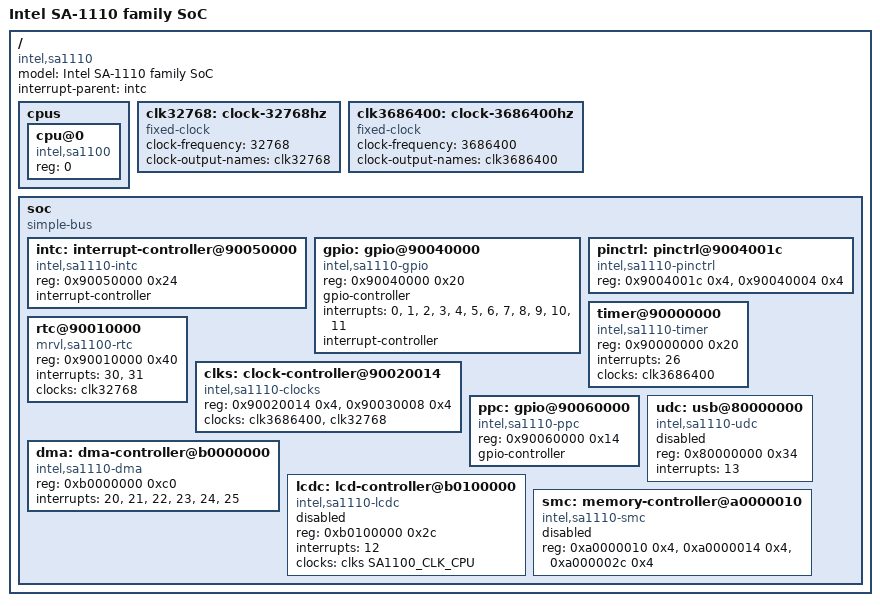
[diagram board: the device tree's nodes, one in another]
// SPDX-License-Identifier: GPL-2.0-or-later
/*
 * sa1110.dtsi - Device Tree Include file for the Intel SA-1110 SoC
 *
 * Copyright (C) 2026 Koen Kooi
 */

#include <dt-bindings/clock/intel,sa1100-clocks.h>

/ {
	#address-cells = <1>;
	#size-cells = <1>;
	model = "Intel SA-1110 family SoC";
	compatible = "intel,sa1110";
	interrupt-parent = <&intc>;

	cpus {
		#address-cells = <1>;
		#size-cells = <0>;

		cpu@0 {
			device_type = "cpu";
			/*
			 * Not "intel,sa1110": that is the board root fallback
			 * compatible, and arm/cpus.yaml matches any node with a
			 * compatible from its enum, so using it here makes the
			 * cpu schema apply to the root node as well. The
			 * SA-1100 compatible describes the same core.
			 */
			compatible = "intel,sa1100";
			reg = <0>;
		};
	};

	/* The crystal references the timer and the RTC are clocked from. */
	clk32768: clock-32768hz {
		compatible = "fixed-clock";
		#clock-cells = <0>;
		clock-frequency = <32768>;
		clock-output-names = "clk32768";
	};

	clk3686400: clock-3686400hz {
		compatible = "fixed-clock";
		#clock-cells = <0>;
		clock-frequency = <3686400>;
		clock-output-names = "clk3686400";
	};

	soc {
		compatible = "simple-bus";
		#address-cells = <1>;
		#size-cells = <1>;
		ranges;

		/* The interrupt controller has no per-line trigger type. */
		intc: interrupt-controller@90050000 {
			compatible = "intel,sa1110-intc", "intel,sa1100-intc";
			reg = <0x90050000 0x24>;
			interrupt-controller;
			#interrupt-cells = <1>;
		};

		/*
		 * The GPIO block is edge-only. GPIO0-10 each have their own
		 * interrupt controller line, GPIO11-27 share one.
		 */
		gpio: gpio@90040000 {
			compatible = "intel,sa1110-gpio", "intel,sa1100-gpio";
			reg = <0x90040000 0x20>;
			gpio-controller;
			#gpio-cells = <2>;
			interrupts = <0>, <1>, <2>, <3>, <4>, <5>, <6>, <7>,
				     <8>, <9>, <10>, <11>;
			interrupt-controller;
			#interrupt-cells = <2>;
		};

		/*
		 * GAFR and GPDR again, as a pin controller. It is a separate
		 * node and driver from "gpio" above, as on PXA: gpio-sa1100.c
		 * is registered from IRQCHIP_DECLARE, so of_platform_populate()
		 * never creates a platform_device for it, and the pinctrl core
		 * needs a real struct device. The two "reg" windows overlap
		 * "gpio" on purpose, since GAFR and GPDR are two registers of
		 * the same block and the pinctrl driver does not claim the
		 * region exclusively. There is no "gpio-ranges" on "gpio":
		 * sa1100_init_gpio() adds the gpiochip at IRQCHIP_DECLARE time,
		 * long before this device exists, and cannot defer.
		 */
		pinctrl: pinctrl@9004001c {
			compatible = "intel,sa1110-pinctrl", "intel,sa1100-pinctrl";
			reg = <0x9004001c 0x4>, <0x90040004 0x4>;
			reg-names = "gafr", "gpdr";
		};

		/*
		 * The OS timer, which is also the watchdog: with OWER.WME set,
		 * a match on OSMR3 resets the SoC. The watchdog has no node of
		 * its own; its registers, counter and clock are this block's.
		 * The register layout is the PXA one, hence the fallback.
		 */
		timer@90000000 {
			compatible = "intel,sa1110-timer", "intel,sa1100-timer",
				     "marvell,pxa-timer";
			reg = <0x90000000 0x20>;
			interrupts = <26>;
			clocks = <&clk3686400>;
		};

		rtc@90010000 {
			compatible = "mrvl,sa1100-rtc";
			reg = <0x90010000 0x40>;
			interrupts = <30>, <31>;
			interrupt-names = "rtc 1Hz", "rtc alarm";
			clocks = <&clk32768>;
		};

		/*
		 * PPCR of the power manager and TUCR of the reset controller,
		 * the only two clock controls of the chip, each a single word
		 * in a block that has other owners.
		 */
		clks: clock-controller@90020014 {
			compatible = "intel,sa1110-clocks", "intel,sa1100-clocks";
			reg = <0x90020014 0x4>, <0x90030008 0x4>;
			reg-names = "ppcr", "tucr";
			clocks = <&clk3686400>, <&clk32768>;
			clock-names = "pxtal", "txtal";
			#clock-cells = <1>;
		};

		/*
		 * Only PPDR..PPFR: HSCR2 (+0x28) and MCCR1 (+0x30) live in the
		 * same page and must not be claimed by this node.
		 */
		ppc: gpio@90060000 {
			compatible = "intel,sa1110-ppc";
			reg = <0x90060000 0x14>;
			gpio-controller;
			#gpio-cells = <2>;
		};

		/*
		 * The six-channel DMA controller. Each channel is wired to a
		 * fixed peripheral, so "#dma-cells" is the 4-bit DDAR device
		 * select field, which the driver's chan_desc[] table is indexed
		 * by (0 = Ser0UDCTr ... 14 = Ser4SSPTr, 15 = Ser4SSPRc), not a
		 * channel number. The node is only for the devicetree probe
		 * path: mach-sa1100 registers the same hardware as a legacy
		 * platform device on a non-devicetree boot and skips it on a
		 * devicetree one.
		 */
		dma: dma-controller@b0000000 {
			compatible = "intel,sa1110-dma", "intel,sa1100-dma";
			reg = <0xb0000000 0xc0>;
			interrupts = <20>, <21>, <22>, <23>, <24>, <25>;
			#dma-cells = <1>;
		};

		/*
		 * Disabled until a board provides a panel behind an OF graph
		 * port. The pixel clock divides the core clock.
		 */
		lcdc: lcd-controller@b0100000 {
			compatible = "intel,sa1110-lcdc", "intel,sa1100-lcdc";
			reg = <0xb0100000 0x2c>;
			interrupts = <12>;
			clocks = <&clks SA1100_CLK_CPU>;
			status = "disabled";
		};

		/*
		 * The USB device controller, Ser0UDCCR to Ser0UDCSR. It has a
		 * fixed three endpoints: ep0 control, one bulk-OUT and one
		 * bulk-IN, with no interrupt endpoint. The interrupt is ICIP
		 * bit 13, one less than IRQ_Ser0UDC in mach/irqs.h like the
		 * other on-chip blocks. It stays disabled until a board adds a
		 * VBUS sense connector and enables it.
		 */
		udc: usb@80000000 {
			compatible = "intel,sa1110-udc", "intel,sa1100-udc";
			reg = <0x80000000 0x34>;
			interrupts = <13>;
			status = "disabled";
		};

		/*
		 * MSC0/MSC1/MSC2, the static memory half of the memory
		 * controller, with one 16-bit timing half per chip select. The
		 * three "reg" entries are separate because the registers are not
		 * contiguous: MECR (PCMCIA) and MDREFR (DRAM refresh and the
		 * cpufreq path) sit between MSC1 and MSC2 and belong to other
		 * code, so one window would claim them too.
		 *
		 * "ranges" carries all six chip selects. Where each one decodes
		 * is fixed by the silicon, 128 MiB apart, and is not a board
		 * choice; a board describes only which of them it populates, as
		 * child nodes with their own timing.
		 *
		 * It is disabled until a board opts in: with no child on any chip
		 * select there is nothing to program, and leaving every chip
		 * select as the firmware set it is the correct behaviour.
		 */
		smc: memory-controller@a0000010 {
			compatible = "intel,sa1110-smc";
			reg = <0xa0000010 0x4>,
			      <0xa0000014 0x4>,
			      <0xa000002c 0x4>;
			reg-names = "msc0", "msc1", "msc2";
			#address-cells = <2>;
			#size-cells = <1>;
			ranges = <0 0 0x00000000 0x08000000>,
				 <1 0 0x08000000 0x08000000>,
				 <2 0 0x10000000 0x08000000>,
				 <3 0 0x18000000 0x08000000>,
				 <4 0 0x40000000 0x08000000>,
				 <5 0 0x48000000 0x08000000>;
			status = "disabled";
		};
	};
};
